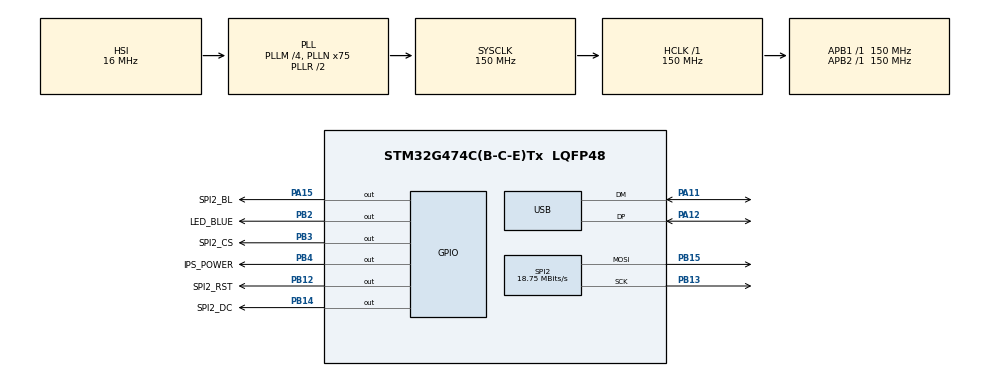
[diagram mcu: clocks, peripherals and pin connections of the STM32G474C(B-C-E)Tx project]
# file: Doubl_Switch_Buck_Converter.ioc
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Mcu.Family=STM32G4
Mcu.Name=STM32G474C(B-C-E)Tx
Mcu.Package=LQFP48
NVIC.PriorityGroup=NVIC_PRIORITYGROUP_4
PA11.Mode=Device
PA11.Signal=USB_DM
PA12.Mode=Device
PA12.Signal=USB_DP
PA13.Mode=Serial_Wire
PA13.Signal=SYS_JTMS-SWDIO
PA14.Mode=Serial_Wire
PA14.Signal=SYS_JTCK-SWCLK
PA15.GPIO_Label=SPI2_BL
PA15.Signal=GPIO_Output
PB12.GPIO_Label=SPI2_RST
PB12.Signal=GPIO_Output
PB13.Mode=TX_Only_Simplex_Unidirect_Master
PB13.Signal=SPI2_SCK
PB14.GPIO_Label=SPI2_DC
PB14.Signal=GPIO_Output
PB15.Mode=TX_Only_Simplex_Unidirect_Master
PB15.Signal=SPI2_MOSI
PB2.GPIO_Label=LED_BLUE
PB2.Signal=GPIO_Output
PB3.GPIO_Label=SPI2_CS
PB3.Signal=GPIO_Output
PB4.GPIO_Label=IPS_POWER
PB4.Signal=GPIO_Output
PF0-OSC_IN.Mode=HSE-External-Oscillator
PF0-OSC_IN.Signal=RCC_OSC_IN
PF1-OSC_OUT.Mode=HSE-External-Oscillator
PF1-OSC_OUT.Signal=RCC_OSC_OUT
ProjectManager.HeapSize=0x200
ProjectManager.StackSize=0x400
ProjectManager.TargetToolchain=MDK-ARM V5.32
RCC.ADC12Freq_Value=150000000
RCC.ADC345Freq_Value=150000000
RCC.AHBFreq_Value=150000000
RCC.APB1Freq_Value=150000000
RCC.APB1TimFreq_Value=150000000
RCC.APB2Freq_Value=150000000
RCC.APB2TimFreq_Value=150000000
RCC.CK48CLockSelection=RCC_USBCLKSOURCE_HSI48
RCC.CortexFreq_Value=150000000
RCC.EXTERNAL_CLOCK_VALUE=12288000
RCC.HCLKFreq_Value=150000000
RCC.HSE_VALUE=16000000
RCC.HSI48_VALUE=48000000
RCC.HSI_VALUE=16000000
RCC.LSE_VALUE=32768
RCC.PLLM=RCC_PLLM_DIV4
RCC.PLLN=75
RCC.SYSCLKFreq_VALUE=150000000
RCC.SYSCLKSource=RCC_SYSCLKSOURCE_PLLCLK
RCC.USBFreq_Value=48000000
RCC.VCOOutputFreq_Value=300000000
SPI2.BaudRatePrescaler=SPI_BAUDRATEPRESCALER_8
SPI2.CalculateBaudRate=18.75 MBits/s
SPI2.DataSize=SPI_DATASIZE_8BIT
SPI2.Direction=SPI_DIRECTION_2LINES
SPI2.Mode=SPI_MODE_MASTER
SPI2.VirtualType=VM_MASTER
VP_SYS_VS_DBSignals.Mode=DisableDeadBatterySignals
board=custom

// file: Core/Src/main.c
/* USER CODE BEGIN Header */
/**
  ******************************************************************************
  * @file           : main.c
  * @brief          : Main program body
  ******************************************************************************
  * @attention
  *
  * Copyright (c) 2024 STMicroelectronics.
  * All rights reserved.
  *
  * This software is licensed under terms that can be found in the LICENSE file
  * in the root directory of this software component.
  * If no LICENSE file comes with this software, it is provided AS-IS.
  *
  ******************************************************************************
  */
/* USER CODE END Header */
#include "main.h"
#include "spi.h"
#include "usb.h"
#include "gpio.h"

/* USER CODE BEGIN Includes */
#include "st7735.h"
#include "fonts.h"
/* USER CODE END Includes */

void SystemClock_Config(void);

int main(void)
{

  /* MCU Configuration--------------------------------------------------------*/

  /* Reset of all peripherals, Initializes the Flash interface and the Systick. */
  HAL_Init();

  /* Configure the system clock */
  SystemClock_Config();

  /* Initialize all configured peripherals */
  MX_GPIO_Init();
  MX_USB_PCD_Init();
  MX_SPI2_Init();
  /* USER CODE BEGIN 2 */
	ST7735_Init();
	HAL_GPIO_WritePin (IPS_POWER_GPIO_Port ,IPS_POWER_Pin ,GPIO_PIN_SET );
	HAL_GPIO_WritePin (SPI2_BL_GPIO_Port ,SPI2_BL_Pin ,GPIO_PIN_SET );
	ST7735_FillScreen(ST7735_BLACK);

  /* USER CODE END 2 */

  /* Infinite loop */
  while (1)
  {

    /* USER CODE BEGIN 3 */

	  HAL_GPIO_WritePin (LED_BLUE_GPIO_Port ,LED_BLUE_Pin ,GPIO_PIN_RESET );
	  HAL_Delay (100);
	  HAL_GPIO_WritePin (LED_BLUE_GPIO_Port ,LED_BLUE_Pin ,GPIO_PIN_SET );
	  HAL_Delay (100);

			/*?FOC??***********************************************************************
	ST7735_DrawString(0, 0, "[INIT]", ST7735_YELLOW, ST7735_BLACK, &Font_11x18);
						//ST7735_DrawString(0, 0, "abcdefghigklim", ST7735_YELLOW, ST7735_BLACK, &Font_8x10);
						//ST7735_DrawString(0, 20, "abcdefghigklim", ST7735_YELLOW, ST7735_BLACK, &Font_7x10);
	ST7735_DrawString(75, 0, "V_IN:", ST7735_GRAY, ST7735_BLACK, &Font_7x10);
	ST7735_DrawString(110, 0, "NO-DC", ST7735_RED, ST7735_BLACK, &Font_7x10);
	ST7735_DrawString(145, 0, " V", ST7735_GRAY, ST7735_BLACK, &Font_7x10);

	ST7735_DrawString(75, 10, "I_IN:", ST7735_GRAY, ST7735_BLACK, &Font_7x10);
 	ST7735_DrawString(110, 10, "0.00", ST7735_GREEN, ST7735_BLACK, &Font_7x10);
	ST7735_DrawString(145, 10, " A", ST7735_GRAY, ST7735_BLACK, &Font_7x10);
	ST7735_DrawString(0, 0, "[INIT]", ST7735_YELLOW, ST7735_BLACK, &Font_11x18);

	ST7735_DrawString(0, 21, "OUT", ST7735_RED, ST7735_BLACK, &Font_11x18);
	ST7735_DrawString(40, 21, "88.8", ST7735_GREEN, ST7735_BLACK, &Font_11x18);
	ST7735_DrawString(85, 21, "V", ST7735_BLUE, ST7735_BLACK, &Font_11x18);
	ST7735_DrawString(110, 21, "8.8", ST7735_GREEN, ST7735_BLACK, &Font_11x18);
	ST7735_DrawString(145, 21, "A", ST7735_BLUE, ST7735_BLACK, &Font_11x18);

	ST7735_DrawString(0, 40, "Current Mode :", ST7735_WHITE, ST7735_BLACK, &Font_7x10);
	ST7735_DrawString(110, 40, "BUCK", ST7735_YELLOW, ST7735_BLACK, &Font_7x10);
	ST7735_DrawString(0, 50, "CAN   : ", ST7735_WHITE, ST7735_BLACK, &Font_7x10);
	ST7735_DrawString(60, 50, "OK!", ST7735_GREEN, ST7735_BLACK, &Font_7x10);
	ST7735_DrawString(0, 60, "USART : ", ST7735_WHITE, ST7735_BLACK, &Font_7x10);
	ST7735_DrawString(60, 60, "OK!", ST7735_GREEN, ST7735_BLACK, &Font_7x10);
 	ST7735_DrawString(0, 70, "USB   : ", ST7735_WHITE, ST7735_BLACK, &Font_7x10);
	ST7735_DrawString(60, 70, "OK! *-*", ST7735_GREEN, ST7735_BLACK, &Font_7x10);

		// *************************************************************************/
		ST7735_DrawImage(120,50, 30,30, gImage_011);

  }
  /* USER CODE END 3 */
}

void SystemClock_Config(void)
{
  RCC_OscInitTypeDef RCC_OscInitStruct = {0};
  RCC_ClkInitTypeDef RCC_ClkInitStruct = {0};

  /** Configure the main internal regulator output voltage
  */
  HAL_PWREx_ControlVoltageScaling(PWR_REGULATOR_VOLTAGE_SCALE1);

  /** Initializes the RCC Oscillators according to the specified parameters
  * in the RCC_OscInitTypeDef structure.
  */
  RCC_OscInitStruct.OscillatorType = RCC_OSCILLATORTYPE_HSI|RCC_OSCILLATORTYPE_HSI48;
  RCC_OscInitStruct.HSIState = RCC_HSI_ON;
  RCC_OscInitStruct.HSICalibrationValue = RCC_HSICALIBRATION_DEFAULT;
  RCC_OscInitStruct.HSI48State = RCC_HSI48_ON;
  RCC_OscInitStruct.PLL.PLLState = RCC_PLL_ON;
  RCC_OscInitStruct.PLL.PLLSource = RCC_PLLSOURCE_HSI;
  RCC_OscInitStruct.PLL.PLLM = RCC_PLLM_DIV4;
  RCC_OscInitStruct.PLL.PLLN = 75;
  RCC_OscInitStruct.PLL.PLLP = RCC_PLLP_DIV2;
  RCC_OscInitStruct.PLL.PLLQ = RCC_PLLQ_DIV2;
  RCC_OscInitStruct.PLL.PLLR = RCC_PLLR_DIV2;
  if (HAL_RCC_OscConfig(&RCC_OscInitStruct) != HAL_OK)
  {
    Error_Handler();
  }

  /** Initializes the CPU, AHB and APB buses clocks
  */
  RCC_ClkInitStruct.ClockType = RCC_CLOCKTYPE_HCLK|RCC_CLOCKTYPE_SYSCLK
                              |RCC_CLOCKTYPE_PCLK1|RCC_CLOCKTYPE_PCLK2;
  RCC_ClkInitStruct.SYSCLKSource = RCC_SYSCLKSOURCE_PLLCLK;
  RCC_ClkInitStruct.AHBCLKDivider = RCC_SYSCLK_DIV1;
  RCC_ClkInitStruct.APB1CLKDivider = RCC_HCLK_DIV1;
  RCC_ClkInitStruct.APB2CLKDivider = RCC_HCLK_DIV1;

  if (HAL_RCC_ClockConfig(&RCC_ClkInitStruct, FLASH_LATENCY_4) != HAL_OK)
  {
    Error_Handler();
  }
}

void Error_Handler(void)
{
  __disable_irq();
  while (1)
  {
  }
}
